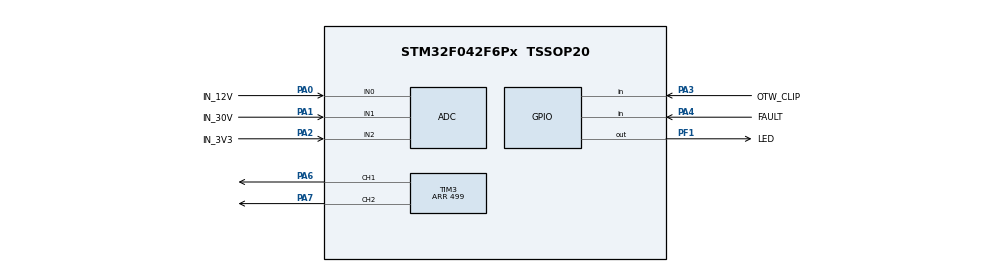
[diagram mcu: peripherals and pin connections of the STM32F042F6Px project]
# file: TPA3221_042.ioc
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Mcu.Family=STM32F0
NVIC.TIM14_IRQn=true\:0\:0\:false\:false\:true\:true\:true
TIM3.CounterMode=TIM_COUNTERMODE_CENTERALIGNED1
TIM3.AutoReloadPreload=TIM_AUTORELOAD_PRELOAD_ENABLE
VP_ADC_TempSens_Input.Mode=IN-TempSens
VP_ADC_Vref_Input.Mode=IN-Vrefint
PA0.GPIO_Label=IN_12V
ADC.ClockPrescaler=ADC_CLOCK_SYNC_PCLK_DIV4
RCC.SYSCLKSource=RCC_SYSCLKSOURCE_HSI48
ProjectManager.StackSize=0x400
PA13.Signal=SYS_SWDIO
ProjectManager.TargetToolchain=STM32CubeIDE
RCC.HCLKFreq_Value=48000000
TIM3.Period=499
PA1.Signal=ADC_IN1
RCC.AHBFreq_Value=48000000
TIM3.Channel-PWM\ Generation1\ CH1=TIM_CHANNEL_1
ADC.SamplingTime=ADC_SAMPLETIME_55CYCLES_5
SH.S_TIM3_CH2.0=TIM3_CH2,PWM Generation2 CH2
board=custom
TIM14.Period=249
PA1.Mode=IN1
PA14.Mode=Serial_Wire
PA1.GPIO_Label=IN_30V
PA0.Mode=IN0
PF1-OSC_OUT.GPIO_Label=LED
SH.S_TIM3_CH1.0=TIM3_CH1,PWM Generation1 CH1
PA13.Mode=Serial_Wire
Mcu.Name=STM32F042F6Px
TIM14.Prescaler=47
PA2.Signal=ADC_IN2
PA0.Signal=ADC_IN0
TIM3.OCPolarity_2=TIM_OCPOLARITY_LOW
PA4.Signal=GPIO_Input
RCC.SYSCLKFreq_VALUE=48000000
Mcu.Package=TSSOP20
PA6.Signal=S_TIM3_CH1
PA2.GPIO_Label=IN_3V3
PA14.Signal=SYS_SWCLK
ProjectManager.HeapSize=0x200
TIM3.Channel-PWM\ Generation2\ CH2=TIM_CHANNEL_2
RCC.APB1TimFreq_Value=48000000
PA2.Mode=IN2
TIM3.Pulse-PWM\ Generation2\ CH2=500
VP_TIM14_VS_ClockSourceINT.Mode=Enable_Timer
RCC.APB1Freq_Value=48000000
PA4.GPIO_Label=FAULT
PF1-OSC_OUT.Signal=GPIO_Output
PA3.GPIO_Label=OTW_CLIP
PA3.Signal=GPIO_Input
PA7.Signal=S_TIM3_CH2

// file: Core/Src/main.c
/* USER CODE BEGIN Header */
/**
  ******************************************************************************
  * @file           : main.c
  * @brief          : Main program body
  ******************************************************************************
  * @attention
  *
  * <h2><center>&copy; Copyright (c) 2021 STMicroelectronics.
  * All rights reserved.</center></h2>
  *
  * This software component is licensed by ST under BSD 3-Clause license,
  * the "License"; You may not use this file except in compliance with the
  * License. You may obtain a copy of the License at:
  *                        opensource.org/licenses/BSD-3-Clause
  *
  ******************************************************************************
  */
/* USER CODE END Header */
#include "main.h"
#include "adc.h"
#include "tim.h"
#include "gpio.h"

void SystemClock_Config(void);

int main(void)
{

  /* MCU Configuration--------------------------------------------------------*/

  /* Reset of all peripherals, Initializes the Flash interface and the Systick. */

  LL_APB1_GRP2_EnableClock(LL_APB1_GRP2_PERIPH_SYSCFG);
  LL_APB1_GRP1_EnableClock(LL_APB1_GRP1_PERIPH_PWR);

  /* System interrupt init*/

  /* Configure the system clock */
  SystemClock_Config();

  /* Initialize all configured peripherals */
  MX_GPIO_Init();
  MX_TIM3_Init();
  MX_TIM14_Init();
  MX_ADC_Init();
  /* USER CODE BEGIN 2 */
  LL_ADC_StartCalibration(ADC1);

  while(LL_ADC_IsCalibrationOnGoing(ADC1))
    {

    }

    LL_ADC_Enable(ADC1);
    LL_TIM_EnableIT_UPDATE(TIM14);
    LL_TIM_EnableCounter(TIM14);

    LL_TIM_EnableCounter(TIM3);
    LL_TIM_CC_EnableChannel(TIM3, LL_TIM_CHANNEL_CH1|LL_TIM_CHANNEL_CH2);
    LL_TIM_EnableAllOutputs(TIM3);

  /* USER CODE END 2 */

  /* Infinite loop */
  while (1)
  {

  }
}

void SystemClock_Config(void)
{
  LL_FLASH_SetLatency(LL_FLASH_LATENCY_1);
  while(LL_FLASH_GetLatency() != LL_FLASH_LATENCY_1)
  {
  }
  LL_RCC_HSI48_Enable();

   /* Wait till HSI48 is ready */
  while(LL_RCC_HSI48_IsReady() != 1)
  {

  }
  LL_RCC_SetAHBPrescaler(LL_RCC_SYSCLK_DIV_1);
  LL_RCC_SetAPB1Prescaler(LL_RCC_APB1_DIV_1);
  LL_RCC_SetSysClkSource(LL_RCC_SYS_CLKSOURCE_HSI48);

   /* Wait till System clock is ready */
  while(LL_RCC_GetSysClkSource() != LL_RCC_SYS_CLKSOURCE_STATUS_HSI48)
  {

  }
  LL_Init1msTick(48000000);
  LL_SetSystemCoreClock(48000000);
}

void Error_Handler(void)
{
  __disable_irq();
  while (1)
  {
  }
}

/************************ (C) COPYRIGHT STMicroelectronics *****END OF FILE****/
